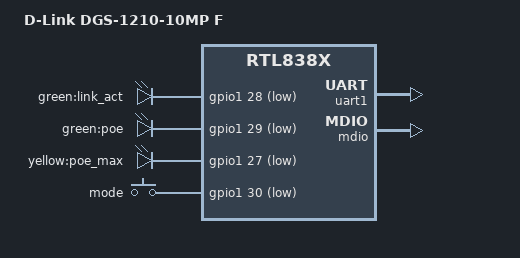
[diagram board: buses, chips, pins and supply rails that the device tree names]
// SPDX-License-Identifier: GPL-2.0-or-later OR MIT

#include "rtl838x.dtsi"
#include "rtl83xx_d-link_dgs-1210_common.dtsi"
#include "rtl83xx_d-link_dgs-1210_gpio.dtsi"

/ {
	compatible = "d-link,dgs-1210-10mp-f", "realtek,rtl8382-soc", "realtek,rtl838x-soc";

	model = "D-Link DGS-1210-10MP F";
};

&leds {
	link_act {
		label = "green:link_act";
		gpios = <&gpio1 28 GPIO_ACTIVE_LOW>;
	};

	poe {
		label = "green:poe";
		gpios = <&gpio1 29 GPIO_ACTIVE_LOW>;
	};

	poe_max {
		label = "yellow:poe_max";
		gpios = <&gpio1 27 GPIO_ACTIVE_LOW>;
	};
};

&keys {
	mode {
		label = "mode";
		gpios = <&gpio1 30 GPIO_ACTIVE_LOW>;
		linux,code = <KEY_LIGHTS_TOGGLE>;
	};
};

&uart1 {
	status = "okay";
};

&ethernet0 {
	mdio: mdio-bus {
		compatible = "realtek,rtl838x-mdio";
		regmap = <&ethernet0>;
		#address-cells = <1>;
		#size-cells = <0>;

		INTERNAL_PHY(8)
		INTERNAL_PHY(9)
		INTERNAL_PHY(10)
		INTERNAL_PHY(11)
		INTERNAL_PHY(12)
		INTERNAL_PHY(13)
		INTERNAL_PHY(14)
		INTERNAL_PHY(15)
		INTERNAL_PHY(24)
		INTERNAL_PHY(26)
	};
};

&switch0 {
	ports {
		#address-cells = <1>;
		#size-cells = <0>;

		SWITCH_PORT(8, 1, internal)
		SWITCH_PORT(9, 2, internal)
		SWITCH_PORT(10, 3, internal)
		SWITCH_PORT(11, 4, internal)
		SWITCH_PORT(12, 5, internal)
		SWITCH_PORT(13, 6, internal)
		SWITCH_PORT(14, 7, internal)
		SWITCH_PORT(15, 8, internal)
		SWITCH_SFP_PORT(24, 9, rgmii-id)
		SWITCH_SFP_PORT(26, 10, rgmii-id)

		port@28 {
			ethernet = <&ethernet0>;
			reg = <28>;
			phy-mode = "internal";
			fixed-link {
				speed = <1000>;
				full-duplex;
			};
		};
	};
};
